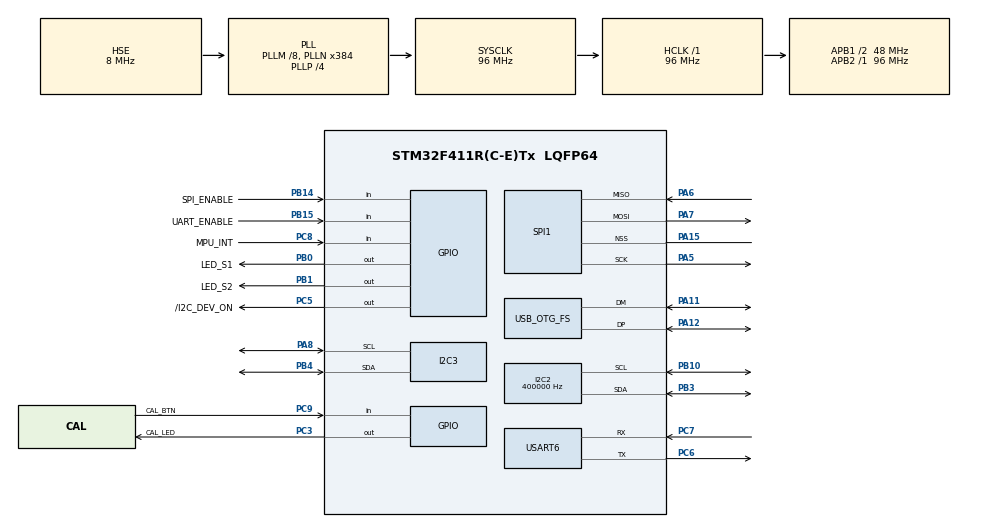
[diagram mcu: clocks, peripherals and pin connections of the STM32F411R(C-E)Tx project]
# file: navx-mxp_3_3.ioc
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I2C2.ClockSpeed=400000
Mcu.Family=STM32F4
Mcu.Name=STM32F411R(C-E)Tx
Mcu.Package=LQFP64
NVIC.I2C3_ER_IRQn=true\:0\:0
NVIC.I2C3_EV_IRQn=true\:0\:0
NVIC.OTG_FS_IRQn=true\:0\:0
NVIC.PriorityGroup=NVIC_PRIORITYGROUP_0
NVIC.SPI1_IRQn=true\:0\:0
NVIC.USART6_IRQn=true\:0\:0
PA11.Mode=Device_Only
PA11.Signal=USB_OTG_FS_DM
PA12.Mode=Device_Only
PA12.Signal=USB_OTG_FS_DP
PA13.Mode=Serial-Wire
PA13.Signal=SYS_JTMS-SWDIO
PA14.Mode=Serial-Wire
PA14.Signal=SYS_JTCK-SWCLK
PA15.Mode=NSS_Signal_Hard
PA15.Signal=SPI1_NSS
PA5.Mode=Full_Duplex_Master
PA5.Signal=SPI1_SCK
PA6.Mode=Full_Duplex_Master
PA6.Signal=SPI1_MISO
PA7.Mode=Full_Duplex_Master
PA7.Signal=SPI1_MOSI
PA8.Mode=I2C
PA8.Signal=I2C3_SCL
PB0.GPIO_Label=LED_S1
PB0.GPIO_ModeDefaultOutputPP=GPIO_MODE_OUTPUT_PP
PB0.GPIO_PuPd=GPIO_NOPULL
PB0.GPIO_Speed=GPIO_SPEED_LOW
PB0.Signal=GPIO_Output
PB1.GPIO_Label=LED_S2
PB1.GPIO_ModeDefaultOutputPP=GPIO_MODE_OUTPUT_PP
PB1.GPIO_PuPd=GPIO_NOPULL
PB1.GPIO_Speed=GPIO_SPEED_LOW
PB1.Signal=GPIO_Output
PB10.Mode=I2C
PB10.Signal=I2C2_SCL
PB14.GPIO_Label=SPI_ENABLE
PB14.GPIO_Mode=GPIO_MODE_INPUT
PB14.GPIO_PuPd=GPIO_NOPULL
PB14.Signal=GPIO_Input
PB15.GPIO_Label=UART_ENABLE
PB15.GPIO_Mode=GPIO_MODE_INPUT
PB15.GPIO_PuPd=GPIO_NOPULL
PB15.Signal=GPIO_Input
PB3.Mode=I2C
PB3.Signal=I2C2_SDA
PB4.Mode=I2C
PB4.Signal=I2C3_SDA
PC3.GPIO_Label=CAL_LED
PC3.GPIO_ModeDefaultOutputPP=GPIO_MODE_OUTPUT_PP
PC3.GPIO_PuPd=GPIO_NOPULL
PC3.GPIO_Speed=GPIO_SPEED_LOW
PC3.Signal=GPIO_Output
PC5.GPIO_Label=/I2C_DEV_ON
PC5.GPIO_ModeDefaultOutputPP=GPIO_MODE_OUTPUT_PP
PC5.GPIO_PuPd=GPIO_NOPULL
PC5.GPIO_Speed=GPIO_SPEED_LOW
PC5.Signal=GPIO_Output
PC6.Mode=Asynchronous
PC6.Signal=USART6_TX
PC7.Mode=Asynchronous
PC7.Signal=USART6_RX
PC8.GPIO_Label=MPU_INT
PC8.GPIO_Mode=GPIO_MODE_INPUT
PC8.GPIO_PuPd=GPIO_NOPULL
PC8.Signal=GPIO_Input
PC9.GPIO_Label=CAL_BTN
PC9.GPIO_Mode=GPIO_MODE_INPUT
PC9.GPIO_PuPd=GPIO_NOPULL
PC9.Signal=GPIO_Input
PH0\ -\ OSC_IN.Mode=HSE-External-Oscillator
PH0\ -\ OSC_IN.Signal=RCC_OSC_IN
PH1\ -\ OSC_OUT.Mode=HSE-External-Oscillator
PH1\ -\ OSC_OUT.Signal=RCC_OSC_OUT
ProjectManager.TargetToolchain=TrueSTUDIO 4.3.1
RCC.48MHZClocksFreq_Value=48000000
RCC.AHBFreq_Value=96000000
RCC.APB1CLKDivider=RCC_HCLK_DIV2
RCC.APB1Freq_Value=48000000
RCC.APB1TimFreq_Value=96000000
RCC.APB2Freq_Value=96000000
RCC.APB2TimFreq_Value=96000000
RCC.ClockTypePCLK1-ClockTree=RCC_CLOCKTYPE_PCLK1
RCC.ClockTypeSysClk-ClockTree=RCC_CLOCKTYPE_SYSCLK
RCC.CortexFreq_Value=12000000
RCC.EnableExtClockForI2S-ClockTree=false
RCC.EnableHSE-ClockTree=true
RCC.EnableHSERTCDevisor-ClockTree=false
RCC.EnableLSE-ClockTree=false
RCC.EnableLSERTC-ClockTree=false
RCC.ExtClockEnable-ClockTree=false
RCC.FLatency-AdvancedSettings=FLASH_LATENCY_3
RCC.HCLKFreq_Value=96000000
RCC.HSEState-ClockTree=RCC_HSE_ON
RCC.HSE_VALUE=8000000
RCC.HSIState-ClockTree=RCC_HSI_OFF
RCC.HSI_VALUE=16000000
RCC.I2SEnable-ClockTree=false
RCC.IWDGEnable-ClockTree=false
RCC.LSE_VALUE=32768
RCC.LSIState-ClockTree=RCC_LSI_OFF
RCC.MCO1OutPutEnable-ClockTree=false
RCC.MCO2OutPutEnable-ClockTree=false
RCC.OscillatorTypeHSE-ClockTree=RCC_OSCILLATORTYPE_HSE
RCC.PLLM=8
RCC.PLLN=384
RCC.PLLP=RCC_PLLP_DIV4
RCC.PLLQ=8
RCC.PLLSource=RCC_PLLSOURCE_HSE
RCC.PLLState-ClockTree=RCC_PLL_ON
RCC.PWR_Regulator_Voltage_Scale-AdvancedSettings=PWR_REGULATOR_VOLTAGE_SCALE2
RCC.RNGEnable-ClockTree=false
RCC.RTCEnable-ClockTree=false
RCC.SDIOEnable-ClockTree=false
RCC.SYSCLKFreq_VALUE=96000000
RCC.SYSCLKSource=RCC_SYSCLKSOURCE_PLLCLK
RCC.USBFSEnable-ClockTree=true
RCC.USBHSEnable-ClockTree=false
RCC.VCOOutputFreq_Value=384000000
SPI1.BaudRatePrescaler-Full_Duplex_Master=SPI_BAUDRATEPRESCALER_4
SPI1.CLKPhase-Full_Duplex_Master=SPI_PHASE_2EDGE
SPI1.CLKPolarity-Full_Duplex_Master=SPI_POLARITY_HIGH
SPI1.CalculateBaudRate-Full_Duplex_Master=24.0 MBits/s
SPI1.Direction-Full_Duplex_Master=SPI_DIRECTION_2LINES
SPI1.Mode-Full_Duplex_Master=SPI_MODE_MASTER
SPI1.NSS-Full_Duplex_Master=SPI_NSS_HARD_INPUT
SPI1.VirtualNSS=VM_NSSHARD
SPI1.VirtualNSS-NSS_Signal_Hard=VM_NSSHARD
SPI1.VirtualType-Full_Duplex_Master=VM_MASTER
USART6.HwFlowCtl-Asynchronous=UART_HWCONTROL_NONE
USART6.VirtualMode-Asynchronous=VM_ASYNC
USB_DEVICE.CLASS_NAME-CDC_FS=CDC
USB_DEVICE.USBD_HandleTypeDef=hUsbDeviceFS
USB_DEVICE.USBD_HandleTypeDef-CDC_FS=hUsbDeviceFS
USB_DEVICE.VirtualMode=Cdc
USB_DEVICE.VirtualMode-CDC_FS=Cdc
USB_DEVICE.VirtualModeFS=Cdc_FS
USB_DEVICE.VirtualModeFS-CDC_FS=Cdc_FS
USB_DEVICE.hUsbDevice-CDC_FS=hDeviceDuSmolt
USB_OTG_FS.VirtualMode-Device_Only=Device_Only
USB_OTG_FS.dma_enable-Device_Only=DISABLE
USB_OTG_FS.low_power_enable-Device_Only=DISABLE
USB_OTG_FS.phy_itface-Device_Only=PCD_PHY_EMBEDDED
USB_OTG_FS.speed-Device_Only=PCD_SPEED_FULL
VP_USB_DEVICE_VS_USB_DEVICE_CDC_FS.Mode=CDC_FS

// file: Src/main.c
/**
  ******************************************************************************
  * File Name          : main.c
  * Date               : 31/10/2014 11:34:34
  * Description        : Main program body
  ******************************************************************************
  *
  * COPYRIGHT(c) 2014 STMicroelectronics
  *
  * Redistribution and use in source and binary forms, with or without modification,
  * are permitted provided that the following conditions are met:
  *   1. Redistributions of source code must retain the above copyright notice,
  *      this list of conditions and the following disclaimer.
  *   2. Redistributions in binary form must reproduce the above copyright notice,
  *      this list of conditions and the following disclaimer in the documentation
  *      and/or other materials provided with the distribution.
  *   3. Neither the name of STMicroelectronics nor the names of its contributors
  *      may be used to endorse or promote products derived from this software
  *      without specific prior written permission.
  *
  * THIS SOFTWARE IS PROVIDED BY THE COPYRIGHT HOLDERS AND CONTRIBUTORS "AS IS"
  * AND ANY EXPRESS OR IMPLIED WARRANTIES, INCLUDING, BUT NOT LIMITED TO, THE
  * IMPLIED WARRANTIES OF MERCHANTABILITY AND FITNESS FOR A PARTICULAR PURPOSE ARE
  * DISCLAIMED. IN NO EVENT SHALL THE COPYRIGHT HOLDER OR CONTRIBUTORS BE LIABLE
  * FOR ANY DIRECT, INDIRECT, INCIDENTAL, SPECIAL, EXEMPLARY, OR CONSEQUENTIAL
  * DAMAGES (INCLUDING, BUT NOT LIMITED TO, PROCUREMENT OF SUBSTITUTE GOODS OR
  * SERVICES; LOSS OF USE, DATA, OR PROFITS; OR BUSINESS INTERRUPTION) HOWEVER
  * CAUSED AND ON ANY THEORY OF LIABILITY, WHETHER IN CONTRACT, STRICT LIABILITY,
  * OR TORT (INCLUDING NEGLIGENCE OR OTHERWISE) ARISING IN ANY WAY OUT OF THE USE
  * OF THIS SOFTWARE, EVEN IF ADVISED OF THE POSSIBILITY OF SUCH DAMAGE.
  *
  ******************************************************************************
  */

#include "stm32f4xx_hal.h"
#include "usb_device.h"
/* USER CODE BEGIN Includes */
#include "navx-mxp.h"
#include "navx-mxp_hal.h"
/* USER CODE END Includes */

I2C_HandleTypeDef hi2c2;
I2C_HandleTypeDef hi2c3;

SPI_HandleTypeDef hspi1;
DMA_HandleTypeDef hdma_spi1_tx;

UART_HandleTypeDef huart6;

void SystemClock_Config(void);
static void MX_GPIO_Init(void);
static void MX_DMA_Init(void);
static void MX_I2C2_Init(void);
static void MX_I2C3_Init(void);
static void MX_SPI1_Init(void);
static void MX_USART6_UART_Init(void);

int main(void)
{

	/* USER CODE BEGIN 1 */
	GPIO_InitTypeDef GPIO_InitStruct;
	int spi_slave_enabled = 0;
	int uart_slave_enabled = 0;

	/* USER CODE END 1 */

	/* MCU Configuration----------------------------------------------------------*/
	/* Reset of all peripherals, Initializes the Flash interface and the Systick. */
	HAL_Init();
	/* Configure the system clock */
	SystemClock_Config();
	MX_GPIO_Init();

	/* In case of soft reset, ensure the USB host    */
	/* sees the D+ USB signal lines low.  Note that  */
	/* the onboard EMI Filter has a 1.5K ohm pullup, */
	/* therefore this causes 2.2mA of current to be  */
	/* sunk into this pin.                           */

	GPIO_InitStruct.Pin = GPIO_PIN_12;
    GPIO_InitStruct.Mode = GPIO_MODE_OUTPUT_PP;
    GPIO_InitStruct.Pull = GPIO_NOPULL;
    GPIO_InitStruct.Speed = GPIO_SPEED_LOW;
    HAL_GPIO_Init(GPIOA, &GPIO_InitStruct);

    /* Wait a bit for the usb host to discover the reset */
	HAL_Delay(1000);

	GPIO_InitStruct.Pin = GPIO_PIN_12;
    GPIO_InitStruct.Mode = GPIO_MODE_INPUT;
    GPIO_InitStruct.Pull = GPIO_NOPULL;
    GPIO_InitStruct.Speed = GPIO_SPEED_LOW;
    HAL_GPIO_Init(GPIOA, &GPIO_InitStruct);

	MX_DMA_Init();
    MX_I2C2_Init();

	HAL_DIP_Switches_Init();
	spi_slave_enabled = HAL_SPI_Slave_Enabled();
	uart_slave_enabled = HAL_UART_Slave_Enabled();

	MX_I2C3_Init();

	if ( spi_slave_enabled ) {
		MX_SPI1_Init();
	}

	if ( uart_slave_enabled ) {
		MX_USART6_UART_Init();
	}

	MX_USB_DEVICE_Init();
	/* USER CODE BEGIN 2 */
	nav10_init();
	/* USER CODE END 2 */

	nav10_main();

	while (1)
	{
	}

}
/** System Clock Configuration
*/
void SystemClock_Config(void)
{

	RCC_OscInitTypeDef RCC_OscInitStruct;
	RCC_ClkInitTypeDef RCC_ClkInitStruct;
	__PWR_CLK_ENABLE();
	__HAL_PWR_VOLTAGESCALING_CONFIG(PWR_REGULATOR_VOLTAGE_SCALE2);
	RCC_OscInitStruct.OscillatorType = RCC_OSCILLATORTYPE_HSE;
	RCC_OscInitStruct.HSEState = RCC_HSE_ON;
	RCC_OscInitStruct.PLL.PLLState = RCC_PLL_ON;
	RCC_OscInitStruct.PLL.PLLSource = RCC_PLLSOURCE_HSE;
	RCC_OscInitStruct.PLL.PLLM = 8;
	RCC_OscInitStruct.PLL.PLLN = 384;
	RCC_OscInitStruct.PLL.PLLP = RCC_PLLP_DIV4;
	RCC_OscInitStruct.PLL.PLLQ = 8;
	HAL_RCC_OscConfig(&RCC_OscInitStruct);
	RCC_ClkInitStruct.ClockType = RCC_CLOCKTYPE_SYSCLK|RCC_CLOCKTYPE_PCLK1;
	RCC_ClkInitStruct.SYSCLKSource = RCC_SYSCLKSOURCE_PLLCLK;
	RCC_ClkInitStruct.AHBCLKDivider = RCC_SYSCLK_DIV1;
	RCC_ClkInitStruct.APB1CLKDivider = RCC_HCLK_DIV2;
	RCC_ClkInitStruct.APB2CLKDivider = RCC_HCLK_DIV1;
	HAL_RCC_ClockConfig(&RCC_ClkInitStruct, FLASH_LATENCY_3);
}

/* I2C2 init function */
void MX_I2C2_Init(void)
{

	hi2c2.Instance = I2C2;
	hi2c2.Init.ClockSpeed =  192000;
	hi2c2.Init.DutyCycle = I2C_DUTYCYCLE_2;
    hi2c2.Init.OwnAddress1 = 0;
    hi2c2.Init.AddressingMode = I2C_ADDRESSINGMODE_7BIT;
    hi2c2.Init.DualAddressMode = I2C_DUALADDRESS_DISABLED;
    hi2c2.Init.OwnAddress2 = 0;
    hi2c2.Init.GeneralCallMode = I2C_GENERALCALL_DISABLED;
    hi2c2.Init.NoStretchMode = I2C_NOSTRETCH_DISABLED;
    HAL_I2C_Init(&hi2c2);
}
/* I2C3 init function */
void MX_I2C3_Init(void)
{

    hi2c3.Instance = I2C3;
    hi2c3.Init.ClockSpeed = 400000;
    hi2c3.Init.DutyCycle = I2C_DUTYCYCLE_2;
    hi2c3.Init.OwnAddress1 = 0x32 << 1;
    hi2c3.Init.AddressingMode = I2C_ADDRESSINGMODE_7BIT;
    hi2c3.Init.DualAddressMode = I2C_DUALADDRESS_DISABLED;
    hi2c3.Init.OwnAddress2 = 0;
    hi2c3.Init.GeneralCallMode = I2C_GENERALCALL_DISABLED;
    hi2c3.Init.NoStretchMode = I2C_NOSTRETCH_DISABLED;
    HAL_I2C_Init(&hi2c3);
}
/* SPI1 init function */
void MX_SPI1_Init(void)
{

	hspi1.Instance = SPI1;
	hspi1.Init.Mode = SPI_MODE_SLAVE;
	hspi1.Init.Direction = SPI_DIRECTION_2LINES;
	hspi1.Init.DataSize = SPI_DATASIZE_8BIT;
	hspi1.Init.CLKPolarity = SPI_POLARITY_HIGH;
	hspi1.Init.CLKPhase = SPI_PHASE_2EDGE;
	hspi1.Init.NSS = SPI_NSS_HARD_INPUT;
	hspi1.Init.BaudRatePrescaler = SPI_BAUDRATEPRESCALER_2;
	hspi1.Init.FirstBit = SPI_FIRSTBIT_MSB;
	hspi1.Init.TIMode = SPI_TIMODE_DISABLED;
	hspi1.Init.CRCCalculation = SPI_CRCCALCULATION_DISABLED;
    HAL_SPI_Init(&hspi1);
}
/* USART6 init function */
void MX_USART6_UART_Init(void)
{

    huart6.Instance = USART6;
    huart6.Init.BaudRate = 57600;
    huart6.Init.WordLength = UART_WORDLENGTH_8B;
    huart6.Init.StopBits = UART_STOPBITS_1;
    huart6.Init.Parity = UART_PARITY_NONE;
    huart6.Init.Mode = UART_MODE_TX_RX;
    huart6.Init.HwFlowCtl = UART_HWCONTROL_NONE;
    huart6.Init.OverSampling = UART_OVERSAMPLING_16;
    HAL_UART_Init(&huart6);
}
/** Configure pins as
        * Analog
        * Input
        * Output
        * EVENT_OUT
        * EXTI
        * Free pins are configured automatically as Analog (this feature is enabled through
        * the Code Generation settings)
*/
void MX_GPIO_Init(void)
{

  GPIO_InitTypeDef GPIO_InitStruct;

  /* GPIO Ports Clock Enable */
  __GPIOC_CLK_ENABLE();
  __GPIOH_CLK_ENABLE();
  __GPIOA_CLK_ENABLE();
  __GPIOB_CLK_ENABLE();
  __GPIOD_CLK_ENABLE();

  /*Configure GPIO pins : PC13 PC14 PC15 PC0
                           PC1 PC2 PC4 PC10
                           PC11 PC12 */
  GPIO_InitStruct.Pin = GPIO_PIN_13|GPIO_PIN_14|GPIO_PIN_15|GPIO_PIN_0
                          |GPIO_PIN_1|GPIO_PIN_2|GPIO_PIN_4|GPIO_PIN_10
                          |GPIO_PIN_11|GPIO_PIN_12;
  GPIO_InitStruct.Mode = GPIO_MODE_ANALOG;
  GPIO_InitStruct.Pull = GPIO_NOPULL;
  HAL_GPIO_Init(GPIOC, &GPIO_InitStruct);

  /*Configure GPIO pins : PC3 PC5 */
  GPIO_InitStruct.Pin = GPIO_PIN_3|GPIO_PIN_5;
  GPIO_InitStruct.Mode = GPIO_MODE_OUTPUT_PP;
  GPIO_InitStruct.Pull = GPIO_NOPULL;
  GPIO_InitStruct.Speed = GPIO_SPEED_LOW;
  HAL_GPIO_Init(GPIOC, &GPIO_InitStruct);

  /*Configure GPIO pins : PA0 PA1 PA2 PA3
                           PA4 PA9 PA10 */
  GPIO_InitStruct.Pin = GPIO_PIN_0|GPIO_PIN_1|GPIO_PIN_2|GPIO_PIN_3
                          |GPIO_PIN_4|GPIO_PIN_9|GPIO_PIN_10;
  GPIO_InitStruct.Mode = GPIO_MODE_ANALOG;
  GPIO_InitStruct.Pull = GPIO_NOPULL;
  HAL_GPIO_Init(GPIOA, &GPIO_InitStruct);

  /*Configure GPIO pins : PB0 PB1 */
  GPIO_InitStruct.Pin = GPIO_PIN_0|GPIO_PIN_1;
  GPIO_InitStruct.Mode = GPIO_MODE_OUTPUT_PP;
  GPIO_InitStruct.Pull = GPIO_NOPULL;
  GPIO_InitStruct.Speed = GPIO_SPEED_LOW;
  HAL_GPIO_Init(GPIOB, &GPIO_InitStruct);

  /*Configure GPIO pins : PB2 PB12 PB13 PB5
                           PB6 PB7 PB8 PB9 */
  GPIO_InitStruct.Pin = GPIO_PIN_2|GPIO_PIN_12|GPIO_PIN_13|GPIO_PIN_5
                          |GPIO_PIN_6|GPIO_PIN_7|GPIO_PIN_8|GPIO_PIN_9;
  GPIO_InitStruct.Mode = GPIO_MODE_ANALOG;
  GPIO_InitStruct.Pull = GPIO_NOPULL;
  HAL_GPIO_Init(GPIOB, &GPIO_InitStruct);

  /*Configure GPIO pins : PB14 PB15 */
  GPIO_InitStruct.Pin = GPIO_PIN_14|GPIO_PIN_15;
  GPIO_InitStruct.Mode = GPIO_MODE_INPUT;
  GPIO_InitStruct.Pull = GPIO_PULLUP;
  HAL_GPIO_Init(GPIOB, &GPIO_InitStruct);

  /*Configure GPIO pins : PC9 */
  GPIO_InitStruct.Pin = GPIO_PIN_9;
  GPIO_InitStruct.Mode = GPIO_MODE_INPUT;
  GPIO_InitStruct.Pull = GPIO_NOPULL;
  HAL_GPIO_Init(GPIOC, &GPIO_InitStruct);

  /*Configure GPIO pin : PD2 */
  GPIO_InitStruct.Pin = GPIO_PIN_2;
  GPIO_InitStruct.Mode = GPIO_MODE_ANALOG;
  GPIO_InitStruct.Pull = GPIO_NOPULL;
  HAL_GPIO_Init(GPIOD, &GPIO_InitStruct);

}

void MX_DMA_Init(void)
{
  /* DMA controller clock enable */
  //__DMA1_CLK_ENABLE();
  __DMA2_CLK_ENABLE();

  /* DMA interrupt init */
  HAL_NVIC_SetPriority(DMA2_Stream2_IRQn, 1, 1);
  HAL_NVIC_EnableIRQ(DMA2_Stream2_IRQn);
  //HAL_NVIC_SetPriority(DMA2_Stream6_IRQn, 0, 0);
  //HAL_NVIC_EnableIRQ(DMA2_Stream6_IRQn);
  //HAL_NVIC_SetPriority(DMA1_Stream4_IRQn, 0, 0);
  //HAL_NVIC_EnableIRQ(DMA1_Stream4_IRQn);

}

/************************ (C) COPYRIGHT STMicroelectronics *****END OF FILE****/
